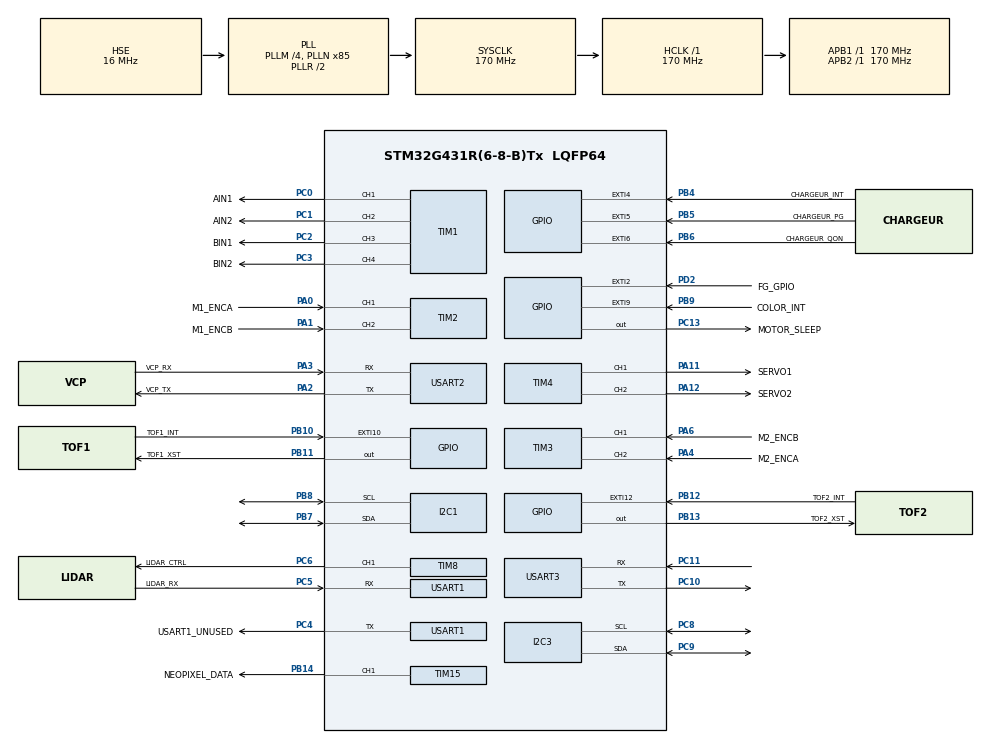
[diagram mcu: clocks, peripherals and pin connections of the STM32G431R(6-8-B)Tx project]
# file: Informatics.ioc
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Dma.Request0=TIM15_CH1
Dma.TIM15_CH1.0.Direction=DMA_MEMORY_TO_PERIPH
Dma.TIM15_CH1.0.EventEnable=DISABLE
Dma.TIM15_CH1.0.Instance=DMA1_Channel1
Dma.TIM15_CH1.0.MemDataAlignment=DMA_MDATAALIGN_HALFWORD
Dma.TIM15_CH1.0.MemInc=DMA_MINC_ENABLE
Dma.TIM15_CH1.0.Mode=DMA_NORMAL
Dma.TIM15_CH1.0.PeriphDataAlignment=DMA_PDATAALIGN_HALFWORD
Dma.TIM15_CH1.0.PeriphInc=DMA_PINC_DISABLE
Dma.TIM15_CH1.0.Polarity=HAL_DMAMUX_REQ_GEN_RISING
Dma.TIM15_CH1.0.Priority=DMA_PRIORITY_LOW
Dma.TIM15_CH1.0.RequestNumber=1
Dma.TIM15_CH1.0.SignalID=NONE
Dma.TIM15_CH1.0.SyncEnable=DISABLE
Dma.TIM15_CH1.0.SyncPolarity=HAL_DMAMUX_SYNC_NO_EVENT
Dma.TIM15_CH1.0.SyncRequestNumber=1
Dma.TIM15_CH1.0.SyncSignalID=NONE
I2C1.Timing=0x40B285C2
I2C3.Timing=0x40B285C2
Mcu.Family=STM32G4
Mcu.Name=STM32G431R(6-8-B)Tx
Mcu.Package=LQFP64
NVIC.DMA1_Channel1_IRQn=true\:0\:0\:false\:false\:true\:false\:true\:true
NVIC.PriorityGroup=NVIC_PRIORITYGROUP_4
PA0.GPIO_Label=M1_ENCA
PA0.Signal=S_TIM2_CH1
PA1.GPIO_Label=M1_ENCB
PA1.Signal=S_TIM2_CH2
PA11.GPIO_Label=SERVO1
PA11.Signal=S_TIM4_CH1
PA12.GPIO_Label=SERVO2
PA12.Signal=S_TIM4_CH2
PA13.Mode=Trace_Asynchronous_SW
PA13.Signal=SYS_JTMS-SWDIO
PA14.Mode=Trace_Asynchronous_SW
PA14.Signal=SYS_JTCK-SWCLK
PA2.GPIO_Label=VCP_TX
PA2.Mode=Asynchronous
PA2.Signal=USART2_TX
PA3.GPIO_Label=VCP_RX
PA3.Mode=Asynchronous
PA3.Signal=USART2_RX
PA4.GPIO_Label=M2_ENCA
PA4.Signal=S_TIM3_CH2
PA6.GPIO_Label=M2_ENCB
PA6.Signal=S_TIM3_CH1
PB10.GPIO_Label=TOF1_INT
PB10.Signal=GPXTI10
PB11.GPIO_Label=TOF1_XST
PB11.Signal=GPIO_Output
PB12.GPIO_Label=TOF2_INT
PB12.Signal=GPXTI12
PB13.GPIO_Label=TOF2_XST
PB13.Signal=GPIO_Output
PB14.GPIO_Label=NEOPIXEL_DATA
PB14.Signal=S_TIM15_CH1
PB3.Mode=Trace_Asynchronous_SW
PB3.Signal=SYS_JTDO-SWO
PB4.GPIO_Label=CHARGEUR_INT
PB4.Signal=GPXTI4
PB5.GPIO_Label=CHARGEUR_PG
PB5.Signal=GPXTI5
PB6.GPIO_Label=CHARGEUR_QON
PB6.Signal=GPXTI6
PB7.Mode=I2C
PB7.Signal=I2C1_SDA
PB8-BOOT0.Mode=I2C
PB8-BOOT0.Signal=I2C1_SCL
PB9.GPIO_Label=COLOR_INT
PB9.Signal=GPXTI9
PC0.GPIO_Label=AIN1
PC0.Signal=S_TIM1_CH1
PC1.GPIO_Label=AIN2
PC1.Signal=S_TIM1_CH2
PC10.Mode=Asynchronous
PC10.Signal=USART3_TX
PC11.Mode=Asynchronous
PC11.Signal=USART3_RX
PC13.GPIO_Label=MOTOR_SLEEP
PC13.Signal=GPIO_Output
PC2.GPIO_Label=BIN1
PC2.Signal=S_TIM1_CH3
PC3.GPIO_Label=BIN2
PC3.Signal=S_TIM1_CH4
PC4.GPIO_Label=USART1_UNUSED
PC4.Mode=Asynchronous
PC4.Signal=USART1_TX
PC5.GPIO_Label=LIDAR_RX
PC5.Mode=Asynchronous
PC5.Signal=USART1_RX
PC6.GPIO_Label=LIDAR_CTRL
PC6.Signal=S_TIM8_CH1
PC8.Mode=I2C
PC8.Signal=I2C3_SCL
PC9.Mode=I2C
PC9.Signal=I2C3_SDA
PD2.GPIO_Label=FG_GPIO
PD2.Signal=GPXTI2
PF0-OSC_IN.Mode=HSE-External-Oscillator
PF0-OSC_IN.Signal=RCC_OSC_IN
PF1-OSC_OUT.Mode=HSE-External-Oscillator
PF1-OSC_OUT.Signal=RCC_OSC_OUT
ProjectManager.HeapSize=0x200
ProjectManager.StackSize=0x400
ProjectManager.TargetToolchain=CMake
RCC.ADC12Freq_Value=170000000
RCC.AHBFreq_Value=170000000
RCC.APB1Freq_Value=170000000
RCC.APB1TimFreq_Value=170000000
RCC.APB2Freq_Value=170000000
RCC.APB2TimFreq_Value=170000000
RCC.CortexFreq_Value=170000000
RCC.EXTERNAL_CLOCK_VALUE=12288000
RCC.HCLKFreq_Value=170000000
RCC.HSE_VALUE=16000000
RCC.HSI48_VALUE=48000000
RCC.HSI_VALUE=16000000
RCC.LSE_VALUE=32768
RCC.PLLM=RCC_PLLM_DIV4
RCC.PLLN=85
RCC.PLLSourceVirtual=RCC_PLLSOURCE_HSE
RCC.SYSCLKFreq_VALUE=170000000
RCC.SYSCLKSource=RCC_SYSCLKSOURCE_PLLCLK
RCC.USBFreq_Value=170000000
RCC.VCOOutputFreq_Value=340000000
SH.S_TIM15_CH1.0=TIM15_CH1,PWM Generation1 CH1
SH.S_TIM1_CH1.0=TIM1_CH1,PWM Generation1 CH1
SH.S_TIM1_CH2.0=TIM1_CH2,PWM Generation2 CH2
SH.S_TIM1_CH3.0=TIM1_CH3,PWM Generation3 CH3
SH.S_TIM1_CH4.0=TIM1_CH4,PWM Generation4 CH4
SH.S_TIM2_CH1.0=TIM2_CH1,Encoder_Interface
SH.S_TIM2_CH2.0=TIM2_CH2,Encoder_Interface
SH.S_TIM3_CH1.0=TIM3_CH1,Encoder_Interface
SH.S_TIM3_CH2.0=TIM3_CH2,Encoder_Interface
SH.S_TIM4_CH1.0=TIM4_CH1,PWM Generation1 CH1
SH.S_TIM4_CH2.0=TIM4_CH2,PWM Generation2 CH2
SH.S_TIM8_CH1.0=TIM8_CH1,PWM Generation1 CH1
TIM1.Channel-PWM\ Generation1\ CH1=TIM_CHANNEL_1
TIM1.Channel-PWM\ Generation2\ CH2=TIM_CHANNEL_2
TIM1.Channel-PWM\ Generation3\ CH3=TIM_CHANNEL_3
TIM1.Channel-PWM\ Generation4\ CH4=TIM_CHANNEL_4
TIM15.Channel-PWM\ Generation1\ CH1=TIM_CHANNEL_1
TIM4.Channel-PWM\ Generation1\ CH1=TIM_CHANNEL_1
TIM4.Channel-PWM\ Generation2\ CH2=TIM_CHANNEL_2
TIM8.Channel-PWM\ Generation1\ CH1=TIM_CHANNEL_1
USART1.VirtualMode-Asynchronous=VM_ASYNC
USART2.VirtualMode-Asynchronous=VM_ASYNC
USART3.VirtualMode-Asynchronous=VM_ASYNC
VP_SYS_VS_DBSignals.Mode=DisableDeadBatterySignals
VP_TIM15_VS_ClockSourceINT.Mode=Internal
VP_TIM1_VS_ClockSourceINT.Mode=Internal
VP_TIM4_VS_ClockSourceINT.Mode=Internal
VP_TIM8_VS_ClockSourceINT.Mode=Internal
board=custom

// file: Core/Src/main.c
/* USER CODE BEGIN Header */
/**
  ******************************************************************************
  * @file           : main.c
  * @brief          : Main program body
  ******************************************************************************
  * @attention
  *
  * Copyright (c) 2026 STMicroelectronics.
  * All rights reserved.
  *
  * This software is licensed under terms that can be found in the LICENSE file
  * in the root directory of this software component.
  * If no LICENSE file comes with this software, it is provided AS-IS.
  *
  ******************************************************************************
  */
/* USER CODE END Header */
#include "main.h"

/* USER CODE BEGIN Includes */
#include <stdio.h>
/* USER CODE END Includes */

I2C_HandleTypeDef hi2c1;
I2C_HandleTypeDef hi2c3;

TIM_HandleTypeDef htim1;
TIM_HandleTypeDef htim2;
TIM_HandleTypeDef htim3;
TIM_HandleTypeDef htim4;
TIM_HandleTypeDef htim8;
TIM_HandleTypeDef htim15;
DMA_HandleTypeDef hdma_tim15_ch1;

UART_HandleTypeDef huart1;
UART_HandleTypeDef huart2;
UART_HandleTypeDef huart3;

void SystemClock_Config(void);
static void MX_GPIO_Init(void);
static void MX_DMA_Init(void);
static void MX_I2C1_Init(void);
static void MX_I2C3_Init(void);
static void MX_TIM2_Init(void);
static void MX_TIM3_Init(void);
static void MX_USART1_UART_Init(void);
static void MX_USART2_UART_Init(void);
static void MX_USART3_UART_Init(void);
static void MX_TIM1_Init(void);
static void MX_TIM4_Init(void);
static void MX_TIM8_Init(void);
static void MX_TIM15_Init(void);

/* USER CODE BEGIN 0 */
int __io_putchar(int ch)
{
    HAL_UART_Transmit(&huart2, (uint8_t *)&ch, 1, HAL_MAX_DELAY);
    return ch;
}

/* USER CODE END 0 */

int main(void)
{

  /* MCU Configuration--------------------------------------------------------*/

  /* Reset of all peripherals, Initializes the Flash interface and the Systick. */
  HAL_Init();

  /* Configure the system clock */
  SystemClock_Config();

  /* Initialize all configured peripherals */
  MX_GPIO_Init();
  MX_DMA_Init();
  MX_I2C1_Init();
  MX_I2C3_Init();
  MX_TIM2_Init();
  MX_TIM3_Init();
  MX_USART1_UART_Init();
  MX_USART2_UART_Init();
  MX_USART3_UART_Init();
  MX_TIM1_Init();
  MX_TIM4_Init();
  MX_TIM8_Init();
  MX_TIM15_Init();
  /* USER CODE BEGIN 2 */
  printf("Boot OK, SYSCLK = %lu Hz\r\n", HAL_RCC_GetSysClockFreq());
  /* USER CODE END 2 */

  /* Infinite loop */
  while (1)
  {

    /* USER CODE BEGIN 3 */
	  //printf("Hellooooo\n");
	  printf("Tick %lu ms\r\n", HAL_GetTick());
	  HAL_Delay(500);
  }
  /* USER CODE END 3 */
}

void SystemClock_Config(void)
{
  RCC_OscInitTypeDef RCC_OscInitStruct = {0};
  RCC_ClkInitTypeDef RCC_ClkInitStruct = {0};

  /** Configure the main internal regulator output voltage
  */
  HAL_PWREx_ControlVoltageScaling(PWR_REGULATOR_VOLTAGE_SCALE1_BOOST);

  /** Initializes the RCC Oscillators according to the specified parameters
  * in the RCC_OscInitTypeDef structure.
  */
  RCC_OscInitStruct.OscillatorType = RCC_OSCILLATORTYPE_HSE;
  RCC_OscInitStruct.HSEState = RCC_HSE_ON;
  RCC_OscInitStruct.PLL.PLLState = RCC_PLL_ON;
  RCC_OscInitStruct.PLL.PLLSource = RCC_PLLSOURCE_HSE;
  RCC_OscInitStruct.PLL.PLLM = RCC_PLLM_DIV4;
  RCC_OscInitStruct.PLL.PLLN = 85;
  RCC_OscInitStruct.PLL.PLLP = RCC_PLLP_DIV2;
  RCC_OscInitStruct.PLL.PLLQ = RCC_PLLQ_DIV2;
  RCC_OscInitStruct.PLL.PLLR = RCC_PLLR_DIV2;
  if (HAL_RCC_OscConfig(&RCC_OscInitStruct) != HAL_OK)
  {
    Error_Handler();
  }

  /** Initializes the CPU, AHB and APB buses clocks
  */
  RCC_ClkInitStruct.ClockType = RCC_CLOCKTYPE_HCLK|RCC_CLOCKTYPE_SYSCLK
                              |RCC_CLOCKTYPE_PCLK1|RCC_CLOCKTYPE_PCLK2;
  RCC_ClkInitStruct.SYSCLKSource = RCC_SYSCLKSOURCE_PLLCLK;
  RCC_ClkInitStruct.AHBCLKDivider = RCC_SYSCLK_DIV1;
  RCC_ClkInitStruct.APB1CLKDivider = RCC_HCLK_DIV1;
  RCC_ClkInitStruct.APB2CLKDivider = RCC_HCLK_DIV1;

  if (HAL_RCC_ClockConfig(&RCC_ClkInitStruct, FLASH_LATENCY_4) != HAL_OK)
  {
    Error_Handler();
  }
}

static void MX_I2C1_Init(void)
{

  hi2c1.Instance = I2C1;
  hi2c1.Init.Timing = 0x40B285C2;
  hi2c1.Init.OwnAddress1 = 0;
  hi2c1.Init.AddressingMode = I2C_ADDRESSINGMODE_7BIT;
  hi2c1.Init.DualAddressMode = I2C_DUALADDRESS_DISABLE;
  hi2c1.Init.OwnAddress2 = 0;
  hi2c1.Init.OwnAddress2Masks = I2C_OA2_NOMASK;
  hi2c1.Init.GeneralCallMode = I2C_GENERALCALL_DISABLE;
  hi2c1.Init.NoStretchMode = I2C_NOSTRETCH_DISABLE;
  if (HAL_I2C_Init(&hi2c1) != HAL_OK)
  {
    Error_Handler();
  }

  /** Configure Analogue filter
  */
  if (HAL_I2CEx_ConfigAnalogFilter(&hi2c1, I2C_ANALOGFILTER_ENABLE) != HAL_OK)
  {
    Error_Handler();
  }

  /** Configure Digital filter
  */
  if (HAL_I2CEx_ConfigDigitalFilter(&hi2c1, 0) != HAL_OK)
  {
    Error_Handler();
  }

}

static void MX_I2C3_Init(void)
{

  hi2c3.Instance = I2C3;
  hi2c3.Init.Timing = 0x40B285C2;
  hi2c3.Init.OwnAddress1 = 0;
  hi2c3.Init.AddressingMode = I2C_ADDRESSINGMODE_7BIT;
  hi2c3.Init.DualAddressMode = I2C_DUALADDRESS_DISABLE;
  hi2c3.Init.OwnAddress2 = 0;
  hi2c3.Init.OwnAddress2Masks = I2C_OA2_NOMASK;
  hi2c3.Init.GeneralCallMode = I2C_GENERALCALL_DISABLE;
  hi2c3.Init.NoStretchMode = I2C_NOSTRETCH_DISABLE;
  if (HAL_I2C_Init(&hi2c3) != HAL_OK)
  {
    Error_Handler();
  }

  /** Configure Analogue filter
  */
  if (HAL_I2CEx_ConfigAnalogFilter(&hi2c3, I2C_ANALOGFILTER_ENABLE) != HAL_OK)
  {
    Error_Handler();
  }

  /** Configure Digital filter
  */
  if (HAL_I2CEx_ConfigDigitalFilter(&hi2c3, 0) != HAL_OK)
  {
    Error_Handler();
  }

}

static void MX_TIM1_Init(void)
{

  TIM_ClockConfigTypeDef sClockSourceConfig = {0};
  TIM_MasterConfigTypeDef sMasterConfig = {0};
  TIM_OC_InitTypeDef sConfigOC = {0};
  TIM_BreakDeadTimeConfigTypeDef sBreakDeadTimeConfig = {0};

  htim1.Instance = TIM1;
  htim1.Init.Prescaler = 0;
  htim1.Init.CounterMode = TIM_COUNTERMODE_UP;
  htim1.Init.Period = 65535;
  htim1.Init.ClockDivision = TIM_CLOCKDIVISION_DIV1;
  htim1.Init.RepetitionCounter = 0;
  htim1.Init.AutoReloadPreload = TIM_AUTORELOAD_PRELOAD_DISABLE;
  if (HAL_TIM_Base_Init(&htim1) != HAL_OK)
  {
    Error_Handler();
  }
  sClockSourceConfig.ClockSource = TIM_CLOCKSOURCE_INTERNAL;
  if (HAL_TIM_ConfigClockSource(&htim1, &sClockSourceConfig) != HAL_OK)
  {
    Error_Handler();
  }
  if (HAL_TIM_PWM_Init(&htim1) != HAL_OK)
  {
    Error_Handler();
  }
  sMasterConfig.MasterOutputTrigger = TIM_TRGO_RESET;
  sMasterConfig.MasterOutputTrigger2 = TIM_TRGO2_RESET;
  sMasterConfig.MasterSlaveMode = TIM_MASTERSLAVEMODE_DISABLE;
  if (HAL_TIMEx_MasterConfigSynchronization(&htim1, &sMasterConfig) != HAL_OK)
  {
    Error_Handler();
  }
  sConfigOC.OCMode = TIM_OCMODE_PWM1;
  sConfigOC.Pulse = 0;
  sConfigOC.OCPolarity = TIM_OCPOLARITY_HIGH;
  sConfigOC.OCNPolarity = TIM_OCNPOLARITY_HIGH;
  sConfigOC.OCFastMode = TIM_OCFAST_DISABLE;
  sConfigOC.OCIdleState = TIM_OCIDLESTATE_RESET;
  sConfigOC.OCNIdleState = TIM_OCNIDLESTATE_RESET;
  if (HAL_TIM_PWM_ConfigChannel(&htim1, &sConfigOC, TIM_CHANNEL_1) != HAL_OK)
  {
    Error_Handler();
  }
  if (HAL_TIM_PWM_ConfigChannel(&htim1, &sConfigOC, TIM_CHANNEL_2) != HAL_OK)
  {
    Error_Handler();
  }
  if (HAL_TIM_PWM_ConfigChannel(&htim1, &sConfigOC, TIM_CHANNEL_3) != HAL_OK)
  {
    Error_Handler();
  }
  if (HAL_TIM_PWM_ConfigChannel(&htim1, &sConfigOC, TIM_CHANNEL_4) != HAL_OK)
  {
    Error_Handler();
  }
  sBreakDeadTimeConfig.OffStateRunMode = TIM_OSSR_DISABLE;
  sBreakDeadTimeConfig.OffStateIDLEMode = TIM_OSSI_DISABLE;
  sBreakDeadTimeConfig.LockLevel = TIM_LOCKLEVEL_OFF;
  sBreakDeadTimeConfig.DeadTime = 0;
  sBreakDeadTimeConfig.BreakState = TIM_BREAK_DISABLE;
  sBreakDeadTimeConfig.BreakPolarity = TIM_BREAKPOLARITY_HIGH;
  sBreakDeadTimeConfig.BreakFilter = 0;
  sBreakDeadTimeConfig.BreakAFMode = TIM_BREAK_AFMODE_INPUT;
  sBreakDeadTimeConfig.Break2State = TIM_BREAK2_DISABLE;
  sBreakDeadTimeConfig.Break2Polarity = TIM_BREAK2POLARITY_HIGH;
  sBreakDeadTimeConfig.Break2Filter = 0;
  sBreakDeadTimeConfig.Break2AFMode = TIM_BREAK_AFMODE_INPUT;
  sBreakDeadTimeConfig.AutomaticOutput = TIM_AUTOMATICOUTPUT_DISABLE;
  if (HAL_TIMEx_ConfigBreakDeadTime(&htim1, &sBreakDeadTimeConfig) != HAL_OK)
  {
    Error_Handler();
  }
  HAL_TIM_MspPostInit(&htim1);

}

static void MX_TIM2_Init(void)
{

  TIM_Encoder_InitTypeDef sConfig = {0};
  TIM_MasterConfigTypeDef sMasterConfig = {0};

  htim2.Instance = TIM2;
  htim2.Init.Prescaler = 0;
  htim2.Init.CounterMode = TIM_COUNTERMODE_UP;
  htim2.Init.Period = 4294967295;
  htim2.Init.ClockDivision = TIM_CLOCKDIVISION_DIV1;
  htim2.Init.AutoReloadPreload = TIM_AUTORELOAD_PRELOAD_DISABLE;
  sConfig.EncoderMode = TIM_ENCODERMODE_TI1;
  sConfig.IC1Polarity = TIM_ICPOLARITY_RISING;
  sConfig.IC1Selection = TIM_ICSELECTION_DIRECTTI;
  sConfig.IC1Prescaler = TIM_ICPSC_DIV1;
  sConfig.IC1Filter = 0;
  sConfig.IC2Polarity = TIM_ICPOLARITY_RISING;
  sConfig.IC2Selection = TIM_ICSELECTION_DIRECTTI;
  sConfig.IC2Prescaler = TIM_ICPSC_DIV1;
  sConfig.IC2Filter = 0;
  if (HAL_TIM_Encoder_Init(&htim2, &sConfig) != HAL_OK)
  {
    Error_Handler();
  }
  sMasterConfig.MasterOutputTrigger = TIM_TRGO_RESET;
  sMasterConfig.MasterSlaveMode = TIM_MASTERSLAVEMODE_DISABLE;
  if (HAL_TIMEx_MasterConfigSynchronization(&htim2, &sMasterConfig) != HAL_OK)
  {
    Error_Handler();
  }

}

static void MX_TIM3_Init(void)
{

  TIM_Encoder_InitTypeDef sConfig = {0};
  TIM_MasterConfigTypeDef sMasterConfig = {0};

  htim3.Instance = TIM3;
  htim3.Init.Prescaler = 0;
  htim3.Init.CounterMode = TIM_COUNTERMODE_UP;
  htim3.Init.Period = 65535;
  htim3.Init.ClockDivision = TIM_CLOCKDIVISION_DIV1;
  htim3.Init.AutoReloadPreload = TIM_AUTORELOAD_PRELOAD_DISABLE;
  sConfig.EncoderMode = TIM_ENCODERMODE_TI1;
  sConfig.IC1Polarity = TIM_ICPOLARITY_RISING;
  sConfig.IC1Selection = TIM_ICSELECTION_DIRECTTI;
  sConfig.IC1Prescaler = TIM_ICPSC_DIV1;
  sConfig.IC1Filter = 0;
  sConfig.IC2Polarity = TIM_ICPOLARITY_RISING;
  sConfig.IC2Selection = TIM_ICSELECTION_DIRECTTI;
  sConfig.IC2Prescaler = TIM_ICPSC_DIV1;
  sConfig.IC2Filter = 0;
  if (HAL_TIM_Encoder_Init(&htim3, &sConfig) != HAL_OK)
  {
    Error_Handler();
  }
  sMasterConfig.MasterOutputTrigger = TIM_TRGO_RESET;
  sMasterConfig.MasterSlaveMode = TIM_MASTERSLAVEMODE_DISABLE;
  if (HAL_TIMEx_MasterConfigSynchronization(&htim3, &sMasterConfig) != HAL_OK)
  {
    Error_Handler();
  }

}

static void MX_TIM4_Init(void)
{

  TIM_ClockConfigTypeDef sClockSourceConfig = {0};
  TIM_MasterConfigTypeDef sMasterConfig = {0};
  TIM_OC_InitTypeDef sConfigOC = {0};

  htim4.Instance = TIM4;
  htim4.Init.Prescaler = 0;
  htim4.Init.CounterMode = TIM_COUNTERMODE_UP;
  htim4.Init.Period = 65535;
  htim4.Init.ClockDivision = TIM_CLOCKDIVISION_DIV1;
  htim4.Init.AutoReloadPreload = TIM_AUTORELOAD_PRELOAD_DISABLE;
  if (HAL_TIM_Base_Init(&htim4) != HAL_OK)
  {
    Error_Handler();
  }
  sClockSourceConfig.ClockSource = TIM_CLOCKSOURCE_INTERNAL;
  if (HAL_TIM_ConfigClockSource(&htim4, &sClockSourceConfig) != HAL_OK)
  {
    Error_Handler();
  }
  if (HAL_TIM_PWM_Init(&htim4) != HAL_OK)
  {
    Error_Handler();
  }
  sMasterConfig.MasterOutputTrigger = TIM_TRGO_RESET;
  sMasterConfig.MasterSlaveMode = TIM_MASTERSLAVEMODE_DISABLE;
  if (HAL_TIMEx_MasterConfigSynchronization(&htim4, &sMasterConfig) != HAL_OK)
  {
    Error_Handler();
  }
  sConfigOC.OCMode = TIM_OCMODE_PWM1;
  sConfigOC.Pulse = 0;
  sConfigOC.OCPolarity = TIM_OCPOLARITY_HIGH;
  sConfigOC.OCFastMode = TIM_OCFAST_DISABLE;
  if (HAL_TIM_PWM_ConfigChannel(&htim4, &sConfigOC, TIM_CHANNEL_1) != HAL_OK)
  {
    Error_Handler();
  }
  if (HAL_TIM_PWM_ConfigChannel(&htim4, &sConfigOC, TIM_CHANNEL_2) != HAL_OK)
  {
    Error_Handler();
  }
  HAL_TIM_MspPostInit(&htim4);

}

static void MX_TIM8_Init(void)
{

  TIM_ClockConfigTypeDef sClockSourceConfig = {0};
  TIM_MasterConfigTypeDef sMasterConfig = {0};
  TIM_OC_InitTypeDef sConfigOC = {0};
  TIM_BreakDeadTimeConfigTypeDef sBreakDeadTimeConfig = {0};

  htim8.Instance = TIM8;
  htim8.Init.Prescaler = 0;
  htim8.Init.CounterMode = TIM_COUNTERMODE_UP;
  htim8.Init.Period = 65535;
  htim8.Init.ClockDivision = TIM_CLOCKDIVISION_DIV1;
  htim8.Init.RepetitionCounter = 0;
  htim8.Init.AutoReloadPreload = TIM_AUTORELOAD_PRELOAD_DISABLE;
  if (HAL_TIM_Base_Init(&htim8) != HAL_OK)
  {
    Error_Handler();
  }
  sClockSourceConfig.ClockSource = TIM_CLOCKSOURCE_INTERNAL;
  if (HAL_TIM_ConfigClockSource(&htim8, &sClockSourceConfig) != HAL_OK)
  {
    Error_Handler();
  }
  if (HAL_TIM_PWM_Init(&htim8) != HAL_OK)
  {
    Error_Handler();
  }
  sMasterConfig.MasterOutputTrigger = TIM_TRGO_RESET;
  sMasterConfig.MasterOutputTrigger2 = TIM_TRGO2_RESET;
  sMasterConfig.MasterSlaveMode = TIM_MASTERSLAVEMODE_DISABLE;
  if (HAL_TIMEx_MasterConfigSynchronization(&htim8, &sMasterConfig) != HAL_OK)
  {
    Error_Handler();
  }
  sConfigOC.OCMode = TIM_OCMODE_PWM1;
  sConfigOC.Pulse = 0;
  sConfigOC.OCPolarity = TIM_OCPOLARITY_HIGH;
  sConfigOC.OCNPolarity = TIM_OCNPOLARITY_HIGH;
  sConfigOC.OCFastMode = TIM_OCFAST_DISABLE;
  sConfigOC.OCIdleState = TIM_OCIDLESTATE_RESET;
  sConfigOC.OCNIdleState = TIM_OCNIDLESTATE_RESET;
  if (HAL_TIM_PWM_ConfigChannel(&htim8, &sConfigOC, TIM_CHANNEL_1) != HAL_OK)
  {
    Error_Handler();
  }
  sBreakDeadTimeConfig.OffStateRunMode = TIM_OSSR_DISABLE;
  sBreakDeadTimeConfig.OffStateIDLEMode = TIM_OSSI_DISABLE;
  sBreakDeadTimeConfig.LockLevel = TIM_LOCKLEVEL_OFF;
  sBreakDeadTimeConfig.DeadTime = 0;
  sBreakDeadTimeConfig.BreakState = TIM_BREAK_DISABLE;
  sBreakDeadTimeConfig.BreakPolarity = TIM_BREAKPOLARITY_HIGH;
  sBreakDeadTimeConfig.BreakFilter = 0;
  sBreakDeadTimeConfig.BreakAFMode = TIM_BREAK_AFMODE_INPUT;
  sBreakDeadTimeConfig.Break2State = TIM_BREAK2_DISABLE;
  sBreakDeadTimeConfig.Break2Polarity = TIM_BREAK2POLARITY_HIGH;
  sBreakDeadTimeConfig.Break2Filter = 0;
  sBreakDeadTimeConfig.Break2AFMode = TIM_BREAK_AFMODE_INPUT;
  sBreakDeadTimeConfig.AutomaticOutput = TIM_AUTOMATICOUTPUT_DISABLE;
  if (HAL_TIMEx_ConfigBreakDeadTime(&htim8, &sBreakDeadTimeConfig) != HAL_OK)
  {
    Error_Handler();
  }
  HAL_TIM_MspPostInit(&htim8);

}

static void MX_TIM15_Init(void)
{

  TIM_ClockConfigTypeDef sClockSourceConfig = {0};
  TIM_MasterConfigTypeDef sMasterConfig = {0};
  TIM_OC_InitTypeDef sConfigOC = {0};
  TIM_BreakDeadTimeConfigTypeDef sBreakDeadTimeConfig = {0};

  htim15.Instance = TIM15;
  htim15.Init.Prescaler = 0;
  htim15.Init.CounterMode = TIM_COUNTERMODE_UP;
  htim15.Init.Period = 65535;
  htim15.Init.ClockDivision = TIM_CLOCKDIVISION_DIV1;
  htim15.Init.RepetitionCounter = 0;
  htim15.Init.AutoReloadPreload = TIM_AUTORELOAD_PRELOAD_DISABLE;
  if (HAL_TIM_Base_Init(&htim15) != HAL_OK)
  {
    Error_Handler();
  }
  sClockSourceConfig.ClockSource = TIM_CLOCKSOURCE_INTERNAL;
  if (HAL_TIM_ConfigClockSource(&htim15, &sClockSourceConfig) != HAL_OK)
  {
    Error_Handler();
  }
  if (HAL_TIM_PWM_Init(&htim15) != HAL_OK)
  {
    Error_Handler();
  }
  sMasterConfig.MasterOutputTrigger = TIM_TRGO_RESET;
  sMasterConfig.MasterSlaveMode = TIM_MASTERSLAVEMODE_DISABLE;
  if (HAL_TIMEx_MasterConfigSynchronization(&htim15, &sMasterConfig) != HAL_OK)
  {
    Error_Handler();
  }
  sConfigOC.OCMode = TIM_OCMODE_PWM1;
  sConfigOC.Pulse = 0;
  sConfigOC.OCPolarity = TIM_OCPOLARITY_HIGH;
  sConfigOC.OCNPolarity = TIM_OCNPOLARITY_HIGH;
  sConfigOC.OCFastMode = TIM_OCFAST_DISABLE;
  sConfigOC.OCIdleState = TIM_OCIDLESTATE_RESET;
  sConfigOC.OCNIdleState = TIM_OCNIDLESTATE_RESET;
  if (HAL_TIM_PWM_ConfigChannel(&htim15, &sConfigOC, TIM_CHANNEL_1) != HAL_OK)
  {
    Error_Handler();
  }
  sBreakDeadTimeConfig.OffStateRunMode = TIM_OSSR_DISABLE;
  sBreakDeadTimeConfig.OffStateIDLEMode = TIM_OSSI_DISABLE;
  sBreakDeadTimeConfig.LockLevel = TIM_LOCKLEVEL_OFF;
  sBreakDeadTimeConfig.DeadTime = 0;
  sBreakDeadTimeConfig.BreakState = TIM_BREAK_DISABLE;
  sBreakDeadTimeConfig.BreakPolarity = TIM_BREAKPOLARITY_HIGH;
  sBreakDeadTimeConfig.BreakFilter = 0;
  sBreakDeadTimeConfig.AutomaticOutput = TIM_AUTOMATICOUTPUT_DISABLE;
  if (HAL_TIMEx_ConfigBreakDeadTime(&htim15, &sBreakDeadTimeConfig) != HAL_OK)
  {
    Error_Handler();
  }
  HAL_TIM_MspPostInit(&htim15);

}

static void MX_USART1_UART_Init(void)
{

  huart1.Instance = USART1;
  huart1.Init.BaudRate = 115200;
  huart1.Init.WordLength = UART_WORDLENGTH_8B;
  huart1.Init.StopBits = UART_STOPBITS_1;
  huart1.Init.Parity = UART_PARITY_NONE;
  huart1.Init.Mode = UART_MODE_TX_RX;
  huart1.Init.HwFlowCtl = UART_HWCONTROL_NONE;
  huart1.Init.OverSampling = UART_OVERSAMPLING_16;
  huart1.Init.OneBitSampling = UART_ONE_BIT_SAMPLE_DISABLE;
  huart1.Init.ClockPrescaler = UART_PRESCALER_DIV1;
  huart1.AdvancedInit.AdvFeatureInit = UART_ADVFEATURE_NO_INIT;
  if (HAL_UART_Init(&huart1) != HAL_OK)
  {
    Error_Handler();
  }
  if (HAL_UARTEx_SetTxFifoThreshold(&huart1, UART_TXFIFO_THRESHOLD_1_8) != HAL_OK)
  {
    Error_Handler();
  }
  if (HAL_UARTEx_SetRxFifoThreshold(&huart1, UART_RXFIFO_THRESHOLD_1_8) != HAL_OK)
  {
    Error_Handler();
  }
  if (HAL_UARTEx_DisableFifoMode(&huart1) != HAL_OK)
  {
    Error_Handler();
  }

}

static void MX_USART2_UART_Init(void)
{

  huart2.Instance = USART2;
  huart2.Init.BaudRate = 115200;
  huart2.Init.WordLength = UART_WORDLENGTH_8B;
  huart2.Init.StopBits = UART_STOPBITS_1;
  huart2.Init.Parity = UART_PARITY_NONE;
  huart2.Init.Mode = UART_MODE_TX_RX;
  huart2.Init.HwFlowCtl = UART_HWCONTROL_NONE;
  huart2.Init.OverSampling = UART_OVERSAMPLING_16;
  huart2.Init.OneBitSampling = UART_ONE_BIT_SAMPLE_DISABLE;
  huart2.Init.ClockPrescaler = UART_PRESCALER_DIV1;
  huart2.AdvancedInit.AdvFeatureInit = UART_ADVFEATURE_NO_INIT;
  if (HAL_UART_Init(&huart2) != HAL_OK)
  {
    Error_Handler();
  }
  if (HAL_UARTEx_SetTxFifoThreshold(&huart2, UART_TXFIFO_THRESHOLD_1_8) != HAL_OK)
  {
    Error_Handler();
  }
  if (HAL_UARTEx_SetRxFifoThreshold(&huart2, UART_RXFIFO_THRESHOLD_1_8) != HAL_OK)
  {
    Error_Handler();
  }
  if (HAL_UARTEx_DisableFifoMode(&huart2) != HAL_OK)
  {
    Error_Handler();
  }

}

static void MX_USART3_UART_Init(void)
{

  huart3.Instance = USART3;
  huart3.Init.BaudRate = 115200;
  huart3.Init.WordLength = UART_WORDLENGTH_8B;
  huart3.Init.StopBits = UART_STOPBITS_1;
  huart3.Init.Parity = UART_PARITY_NONE;
  huart3.Init.Mode = UART_MODE_TX_RX;
  huart3.Init.HwFlowCtl = UART_HWCONTROL_NONE;
  huart3.Init.OverSampling = UART_OVERSAMPLING_16;
  huart3.Init.OneBitSampling = UART_ONE_BIT_SAMPLE_DISABLE;
  huart3.Init.ClockPrescaler = UART_PRESCALER_DIV1;
  huart3.AdvancedInit.AdvFeatureInit = UART_ADVFEATURE_NO_INIT;
  if (HAL_UART_Init(&huart3) != HAL_OK)
  {
    Error_Handler();
  }
  if (HAL_UARTEx_SetTxFifoThreshold(&huart3, UART_TXFIFO_THRESHOLD_1_8) != HAL_OK)
  {
    Error_Handler();
  }
  if (HAL_UARTEx_SetRxFifoThreshold(&huart3, UART_RXFIFO_THRESHOLD_1_8) != HAL_OK)
  {
    Error_Handler();
  }
  if (HAL_UARTEx_DisableFifoMode(&huart3) != HAL_OK)
  {
    Error_Handler();
  }

}

static void MX_DMA_Init(void)
{

  /* DMA controller clock enable */
  __HAL_RCC_DMAMUX1_CLK_ENABLE();
  __HAL_RCC_DMA1_CLK_ENABLE();

  /* DMA interrupt init */
  /* DMA1_Channel1_IRQn interrupt configuration */
  HAL_NVIC_SetPriority(DMA1_Channel1_IRQn, 0, 0);
  HAL_NVIC_EnableIRQ(DMA1_Channel1_IRQn);

}

static void MX_GPIO_Init(void)
{
  GPIO_InitTypeDef GPIO_InitStruct = {0};

  /* GPIO Ports Clock Enable */
  __HAL_RCC_GPIOC_CLK_ENABLE();
  __HAL_RCC_GPIOF_CLK_ENABLE();
  __HAL_RCC_GPIOA_CLK_ENABLE();
  __HAL_RCC_GPIOB_CLK_ENABLE();
  __HAL_RCC_GPIOD_CLK_ENABLE();

  /*Configure GPIO pin Output Level */
  HAL_GPIO_WritePin(MOTOR_SLEEP_GPIO_Port, MOTOR_SLEEP_Pin, GPIO_PIN_RESET);

  /*Configure GPIO pin Output Level */
  HAL_GPIO_WritePin(GPIOB, TOF1_XST_Pin|TOF2_XST_Pin, GPIO_PIN_RESET);

  /*Configure GPIO pin : MOTOR_SLEEP_Pin */
  GPIO_InitStruct.Pin = MOTOR_SLEEP_Pin;
  GPIO_InitStruct.Mode = GPIO_MODE_OUTPUT_PP;
  GPIO_InitStruct.Pull = GPIO_NOPULL;
  GPIO_InitStruct.Speed = GPIO_SPEED_FREQ_LOW;
  HAL_GPIO_Init(MOTOR_SLEEP_GPIO_Port, &GPIO_InitStruct);

  /*Configure GPIO pins : TOF1_INT_Pin TOF2_INT_Pin CHARGEUR_INT_Pin CHARGEUR_PG_Pin
                           CHARGEUR_QON_Pin COLOR_INT_Pin */
  GPIO_InitStruct.Pin = TOF1_INT_Pin|TOF2_INT_Pin|CHARGEUR_INT_Pin|CHARGEUR_PG_Pin
                          |CHARGEUR_QON_Pin|COLOR_INT_Pin;
  GPIO_InitStruct.Mode = GPIO_MODE_IT_RISING;
  GPIO_InitStruct.Pull = GPIO_NOPULL;
  HAL_GPIO_Init(GPIOB, &GPIO_InitStruct);

  /*Configure GPIO pins : TOF1_XST_Pin TOF2_XST_Pin */
  GPIO_InitStruct.Pin = TOF1_XST_Pin|TOF2_XST_Pin;
  GPIO_InitStruct.Mode = GPIO_MODE_OUTPUT_PP;
  GPIO_InitStruct.Pull = GPIO_NOPULL;
  GPIO_InitStruct.Speed = GPIO_SPEED_FREQ_LOW;
  HAL_GPIO_Init(GPIOB, &GPIO_InitStruct);

  /*Configure GPIO pin : FG_GPIO_Pin */
  GPIO_InitStruct.Pin = FG_GPIO_Pin;
  GPIO_InitStruct.Mode = GPIO_MODE_IT_RISING;
  GPIO_InitStruct.Pull = GPIO_NOPULL;
  HAL_GPIO_Init(FG_GPIO_GPIO_Port, &GPIO_InitStruct);

}

void Error_Handler(void)
{
  __disable_irq();
  while (1)
  {
  }
}
